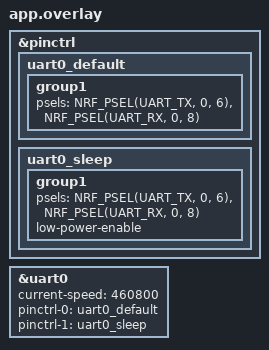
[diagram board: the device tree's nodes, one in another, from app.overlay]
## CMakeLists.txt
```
cmake_minimum_required(VERSION 3.20.0)

find_package(Zephyr REQUIRED HINTS $ENV{ZEPHYR_BASE})
project(gateway_nrf_central)

target_sources(app PRIVATE 
    src/main.c
    src/ble_central_mgr.c
    src/ble_node_slots.c
    src/uart_tx_bridge.c
    src/uart_tx_queue.c
)

target_include_directories(app PRIVATE
    src
    ../common
)
```

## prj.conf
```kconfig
# GPIO Driver
CONFIG_GPIO=y

# Console Output
CONFIG_PRINTK=y

# Zephyr Logging Subsystem
CONFIG_LOG=y
CONFIG_LOG_MODE_DEFERRED=y
CONFIG_LOG_BACKEND_SHOW_COLOR=y

# Output format for UF2 Bootloader
CONFIG_BUILD_OUTPUT_UF2=y

# USB CDC ACM Serial Console
CONFIG_SERIAL=y
CONFIG_CONSOLE=y
CONFIG_UART_CONSOLE=y
CONFIG_USB_DEVICE_STACK_NEXT=y
CONFIG_CDC_ACM_SERIAL_INITIALIZE_AT_BOOT=y
CONFIG_CDC_ACM_SERIAL_ENABLE_AT_BOOT=y

# High-Speed UART Bridge with EasyDMA (UARTE0 @ 460800 bps)
CONFIG_UART_ASYNC_API=y
CONFIG_UART_0_INTERRUPT_DRIVEN=n
CONFIG_UART_0_ASYNC=y


# Bluetooth Subsystem
CONFIG_BT=y
CONFIG_BT_CENTRAL=y
CONFIG_BT_SMP=y
CONFIG_BT_GATT_CLIENT=y

# Multi-Link Configuration (Up to 10 Concurrent Node Connections)
CONFIG_BT_MAX_CONN=10
CONFIG_BT_MAX_PAIRED=10
CONFIG_BT_CONN_TX_MAX=16
CONFIG_BT_BUF_ACL_TX_COUNT=16
CONFIG_BT_BUF_EVT_RX_COUNT=20

# High Throughput & MTU Settings
CONFIG_BT_L2CAP_TX_MTU=247
CONFIG_BT_BUF_ACL_RX_SIZE=251
CONFIG_BT_BUF_ACL_TX_SIZE=251
CONFIG_BT_CTLR_DATA_LENGTH_MAX=251
```

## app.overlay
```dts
&pinctrl {
    uart0_default: uart0_default {
        group1 {
			psels = <NRF_PSEL(UART_TX, 0, 6)>, <NRF_PSEL(UART_RX, 0, 8)>;
		};
    };

    uart0_sleep: uart0_sleep {
        group1 {
			psels = <NRF_PSEL(UART_TX, 0, 6)>, <NRF_PSEL(UART_RX, 0, 8)>;
            low-power-enable;
		};
    };
};

&uart0 {
    status = "okay";
    current-speed = <460800>;
    pinctrl-0 = <&uart0_default>;
    pinctrl-1 = <&uart0_sleep>;
    pinctrl-names = "default", "sleep";
};
```

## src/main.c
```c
#include <stdbool.h>
#include <stdint.h>
#include <string.h>

#include <zephyr/drivers/gpio.h>
#include <zephyr/kernel.h>
#include <zephyr/logging/log.h>
#include <zephyr/sys/printk.h>

#include "ble_central_mgr.h"
#include "ble_protocol_def.h"
#include "uart_frame_def.h"
#include "uart_tx_bridge.h"
#include "uart_tx_queue.h"

LOG_MODULE_REGISTER(gateway_main, LOG_LEVEL_INF);

static const struct gpio_dt_spec user_led = GPIO_DT_SPEC_GET(DT_ALIAS(led0), gpios);
#define LED_BLINK_INTERVAL_MS 1000

static void on_ble_connected(const ble_conn_context_t *ctx, const bt_addr_le_t *addr) {
    ARG_UNUSED(addr);
    uint8_t payload[sizeof(uart_v2_envelope_t) + sizeof(uart_node_status_pkt_t)];
    uart_v2_envelope_t *env = (uart_v2_envelope_t *)payload;
    uart_node_status_pkt_t *status = (uart_node_status_pkt_t *)(payload + sizeof(uart_v2_envelope_t));

    env->bridge_epoch = uart_tx_bridge_get_active_epoch();
    env->session_id = ctx->session_id;
    env->seq = ctx->seq;
    env->central_rx_mono_ms = ctx->rx_mono_ms;

    status->status = 1; /* 1 = Connected */
    memcpy(status->mac, ctx->mac, 6);

    uart_tx_queue_send(ctx->slot_id, UART_PKT_TYPE_NODE_STATUS_V2, payload, sizeof(payload));
}

static void on_ble_disconnected(const ble_conn_context_t *ctx, const bt_addr_le_t *addr, uint8_t reason) {
    ARG_UNUSED(addr);
    ARG_UNUSED(reason);
    uint8_t payload[sizeof(uart_v2_envelope_t) + sizeof(uart_node_status_pkt_t)];
    uart_v2_envelope_t *env = (uart_v2_envelope_t *)payload;
    uart_node_status_pkt_t *status = (uart_node_status_pkt_t *)(payload + sizeof(uart_v2_envelope_t));

    env->bridge_epoch = uart_tx_bridge_get_active_epoch();
    env->session_id = ctx->session_id;
    env->seq = ctx->seq;
    env->central_rx_mono_ms = ctx->rx_mono_ms;

    status->status = 0; /* 0 = Disconnected */
    memcpy(status->mac, ctx->mac, 6);

    uart_tx_queue_send(ctx->slot_id, UART_PKT_TYPE_NODE_STATUS_V2, payload, sizeof(payload));
}

static void on_vitals_received(const ble_conn_context_t *ctx, const vitals_packet_t *vitals) {
    uint8_t payload[sizeof(uart_v2_envelope_t) + sizeof(vitals_packet_t)];
    uart_v2_envelope_t *env = (uart_v2_envelope_t *)payload;

    env->bridge_epoch = uart_tx_bridge_get_active_epoch();
    env->session_id = ctx->session_id;
    env->seq = ctx->seq;
    env->central_rx_mono_ms = ctx->rx_mono_ms;

    memcpy(payload + sizeof(uart_v2_envelope_t), vitals, sizeof(vitals_packet_t));
    uart_tx_queue_send(ctx->slot_id, UART_PKT_TYPE_VITALS_V2, payload, sizeof(payload));
}

static void on_ecg_received(const ble_conn_context_t *ctx, const int16_t *samples, uint16_t count) {
    uint8_t sample_bytes = (uint8_t)(count * sizeof(int16_t));
    if (sample_bytes > 100) {
        sample_bytes = 100;
    }

    uint8_t payload[sizeof(uart_v2_envelope_t) + 100];
    uart_v2_envelope_t *env = (uart_v2_envelope_t *)payload;

    env->bridge_epoch = uart_tx_bridge_get_active_epoch();
    env->session_id = ctx->session_id;
    env->seq = ctx->seq;
    env->central_rx_mono_ms = ctx->rx_mono_ms;

    memcpy(payload + sizeof(uart_v2_envelope_t), samples, sample_bytes);
    uart_tx_queue_send(ctx->slot_id, UART_PKT_TYPE_ECG_V2, payload, (uint8_t)(sizeof(uart_v2_envelope_t) + sample_bytes));
}

static void on_raw_received(const ble_conn_context_t *ctx, const uint8_t *data, uint16_t len) {
    ARG_UNUSED(ctx);
    ARG_UNUSED(data);
    ARG_UNUSED(len);
}

static const ble_central_callbacks_t ble_callbacks = {
    .connected = on_ble_connected,
    .disconnected = on_ble_disconnected,
    .vitals_received = on_vitals_received,
    .ecg_received = on_ecg_received,
    .raw_received = on_raw_received,
};

/* ══════════════════════════════════════════════════════════════
 *  Main Application Entry Point
 * ════════════════════════════════════════════════════════════ */
int main(void) {
    int ret;
    bool led_state = false;
    uint32_t heartbeat_cnt = 0;

    if (gpio_is_ready_dt(&user_led)) {
        gpio_pin_configure_dt(&user_led, GPIO_OUTPUT_ACTIVE);
    }

    printk("\n==================================================\n");
    printk("  [Wearable Gateway] Zephyr BLE Central & Bridge    \n");
    printk("  Board: Pro Micro nRF52840 (UF2)                  \n");
    printk("  Inter-Chip UART Bridge @ 460800 bps              \n");
    printk("==================================================\n\n");

    ret = uart_tx_bridge_init();
    if (ret != 0) {
        LOG_ERR("UART Bridge init failed (%d)", ret);
    }

    uart_tx_queue_init();

    ret = ble_central_mgr_init(&ble_callbacks);
    if (ret != 0) {
        LOG_ERR("BLE Central Manager init failed (err %d)", ret);
    } else {
        LOG_INF("BLE Central Manager initialized. Waiting for '%s'...", BLE_DEV_NAME_PREFIX);
    }

    while (1) {
        gpio_pin_toggle_dt(&user_led);
        led_state = !led_state;

        uart_tx_bridge_poll_handshake();

        uart_tx_queue_stats_t q_stats;
        uint32_t q_pending = uart_tx_queue_get_stats(&q_stats);

        LOG_INF("[HEARTBEAT #%03u] Nodes: %u/10 (Sub: %u) | Q: %u/32 (Sent: %u, Drop: %u) | Uptime: %lld ms",
                heartbeat_cnt++,
                ble_central_mgr_get_connected_count(),
                ble_central_mgr_get_subscribed_count(),
                q_pending,
                q_stats.sent_count,
                q_stats.dropped_count,
                k_uptime_get());

        k_msleep(LED_BLINK_INTERVAL_MS);
    }


    return 0;
}
```

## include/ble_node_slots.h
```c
#ifndef BLE_NODE_SLOTS_H
#define BLE_NODE_SLOTS_H

/* Standard C Libraries */
#include <stdbool.h>
#include <stdint.h>

/* Zephyr System Headers */
#include <zephyr/types.h>
#include <zephyr/bluetooth/bluetooth.h> 
#include <zephyr/bluetooth/conn.h>     
#include <zephyr/bluetooth/gatt.h>      

#ifndef BLE_NODE_MAX_SLOTS
#if defined(CONFIG_BT_MAX_CONN)
#define BLE_NODE_MAX_SLOTS CONFIG_BT_MAX_CONN
#else
#define BLE_NODE_MAX_SLOTS 10U
#endif
#endif


typedef enum {
    NODE_STATE_FREE = 0,
    NODE_STATE_CONNECTING,
    NODE_STATE_CONNECTED,
    NODE_STATE_DISCOVERING,
    NODE_STATE_SUBSCRIBED
} ble_node_state_t ;

typedef struct {
    uint8_t slot_id;                   /* 0 .. 9 */
    bool is_used;
    ble_node_state_t state;
    bt_addr_le_t addr;                 /* MAC của Node */
    struct bt_conn *conn;              /* Con trỏ kết nối Zephyr */
    uint16_t tx_char_val_handle;      
    uint16_t cccd_handle;             
    struct bt_gatt_exchange_params mtu_params;
    struct bt_gatt_discover_params discover_params;
    struct bt_gatt_subscribe_params subscribe_params;
} ble_node_slot_t;

void ble_node_slots_init(void);

  
ble_node_slot_t *ble_node_slot_alloc(const bt_addr_le_t *addr); 

  
void ble_node_slot_free(ble_node_slot_t *slot); 

  
ble_node_slot_t *ble_node_slot_find_by_addr(const bt_addr_le_t *addr);

  
ble_node_slot_t *ble_node_slot_find_by_conn(const struct bt_conn *conn);

  
uint8_t ble_node_slots_get_active_count(void);

  
uint8_t ble_node_slots_get_subscribed_count(void);

#endif
```

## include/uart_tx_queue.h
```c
#ifndef UART_TX_QUEUE_H
#define UART_TX_QUEUE_H

#include <stddef.h>
#include <stdint.h>
#include <stdbool.h>

#include "uart_frame_def.h"

#ifdef __cplusplus
extern "C" {
#endif

#define UART_TX_QUEUE_DEPTH 32

/* Fixed-size flat item struct, aligned to 4 bytes */
typedef struct {
    uint8_t node_id;
    uint8_t pkt_type;
    uint8_t len;
    uint8_t payload[UART_MAX_PAYLOAD_LEN]; /* 128 bytes */
} uart_tx_item_t;

typedef struct {
    uint32_t queued_count;
    uint32_t sent_count;
    uint32_t dropped_count;
    uint32_t error_count;
} uart_tx_queue_stats_t;

/**
 * @brief Initialize the UART TX Queue module and clear stats.
 */
void uart_tx_queue_init(void);

/**
 * @brief Non-blocking producer call to enqueue a frame for transmission.
 *
 * @param node_id Target/Source node index (0..9)
 * @param pkt_type Packet type (UART_PKT_TYPE_*)
 * @param payload Pointer to payload buffer
 * @param len Payload length (1..128)
 * @return 0 on success, -ENOMEM if queue is full, -EINVAL if params invalid
 */
int uart_tx_queue_send(uint8_t node_id, uint8_t pkt_type, const void *payload, uint8_t len);

/**
 * @brief Retrieve an item from the queue (used by consumer worker).
 *
 * @param item Pointer to output item struct
 * @param timeout_ms Timeout in milliseconds (0 = no wait, -1 = forever)
 * @return 0 on success, negative error code otherwise
 */
int uart_tx_queue_get(uart_tx_item_t *item, int32_t timeout_ms);

/**
 * @brief Get queue statistics and current count of pending items.
 *
 * @param stats Output pointer to copy stats into (optional, can be NULL)
 * @return Current number of items waiting in queue
 */
uint32_t uart_tx_queue_get_stats(uart_tx_queue_stats_t *stats);

#ifdef __cplusplus
}
#endif

#endif /* UART_TX_QUEUE_H */
```

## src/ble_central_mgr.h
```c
/*
 * Copyright (c) 2026 Wearable Gateway Project
 *
 * ble_central_mgr.h - BLE Central Manager for Wearable Gateway
 * Handles Active Scanning, Target Node Matching, Connection Lifecycle,
 * ATT MTU Negotiation, GATT Discovery, and Characteristic Subscription.
 */

#ifndef BLE_CENTRAL_MGR_H
#define BLE_CENTRAL_MGR_H

/* Standard C Libraries */
#include <stdbool.h>
#include <stdint.h>

/* Zephyr System Headers */
#include <zephyr/types.h>
#include <zephyr/bluetooth/bluetooth.h>
#include <zephyr/bluetooth/conn.h>

/* Project Local Headers */
#include "ble_node_slots.h"
#include "ble_protocol_def.h"

/**
 * @brief Application event callbacks registered with BLE Central Manager.
 */
typedef struct {
    void (*connected)(const ble_conn_context_t *ctx, const bt_addr_le_t *addr);
    void (*disconnected)(const ble_conn_context_t *ctx, const bt_addr_le_t *addr, uint8_t reason);
    void (*vitals_received)(const ble_conn_context_t *ctx, const vitals_packet_t *vitals);
    void (*ecg_received)(const ble_conn_context_t *ctx, const int16_t *samples, uint16_t count);
    void (*raw_received)(const ble_conn_context_t *ctx, const uint8_t *data, uint16_t len);
} ble_central_callbacks_t;

/**
 * @brief Initialize the Bluetooth stack and start BLE Central manager.
 *
 * @param cbs Pointer to callback structure (must have static/persistent lifetime).
 * @return 0 on success, or negative error code on failure.
 */
int ble_central_mgr_init(const ble_central_callbacks_t *cbs);

/**
 * @brief Check if a peripheral node is currently connected.
 *
 * @return true if connected, false otherwise.
 */
bool ble_central_mgr_is_connected(void);

/**
 * @brief Start active BLE scanning for target nodes.
 *
 * @return 0 on success, or negative error code on failure.
 */
int ble_central_mgr_scan_start(void);

/**
 * @brief Stop active BLE scanning.
 *
 * @return 0 on success, or negative error code on failure.
 */
int ble_central_mgr_scan_stop(void);

uint8_t ble_central_mgr_get_connected_count(void);

uint8_t ble_central_mgr_get_subscribed_count(void);

/**
 * @brief Send a downlink command payload to a node via BLE GATT Write Request (0x1402).
 *
 * @param slot_id Slot index (0 .. BLE_NODE_MAX_SLOTS - 1)
 * @param data    Command payload bytes (e.g. CMD_MODE_CFG, CMD_THR, etc.)
 * @param len     Length of command payload in bytes
 * @return 0 on success, -EINVAL on invalid args, -ENOTCONN if not connected/discovered,
 *         -EBUSY if a write is already in progress for this slot.
 */
int ble_central_mgr_write_cmd(uint8_t slot_id, const uint8_t *data, uint16_t len);

#endif /* BLE_CENTRAL_MGR_H */
```

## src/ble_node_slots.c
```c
/* Standard C Libraries */
#include <stdbool.h>
#include <stdint.h>
#include <string.h>

#ifndef HOST_TEST
/* Zephyr System Headers */
#include <zephyr/kernel.h>
#include <zephyr/logging/log.h>
LOG_MODULE_REGISTER(ble_node_slots, LOG_LEVEL_INF);
#endif

/* Project Local Headers */
#include "ble_node_slots.h"

static ble_node_slot_t s_slots[BLE_NODE_MAX_SLOTS];
static uint32_t s_global_session_counter = 1;

static void convert_addr_to_mac_be(uint8_t *mac_be, const bt_addr_le_t *addr) {
    if (!mac_be) return;
    if (addr) {
        /* Convert Zephyr Little-Endian (addr->a.val[0]=LSB) to Canonical Big-Endian (mac_be[0]=MSB) */
        mac_be[0] = addr->a.val[5];
        mac_be[1] = addr->a.val[4];
        mac_be[2] = addr->a.val[3];
        mac_be[3] = addr->a.val[2];
        mac_be[4] = addr->a.val[1];
        mac_be[5] = addr->a.val[0];
    } else {
        memset(mac_be, 0, 6);
    }
}

static uint32_t allocate_next_session_id(void) {
    uint32_t session = s_global_session_counter++;
    if (session == 0) {
        session = s_global_session_counter++;
    }
    return session;
}

void ble_node_slots_init(void) {
    memset(s_slots, 0, sizeof(s_slots));
    for (uint32_t i = 0; i < BLE_NODE_MAX_SLOTS; i++) {
        s_slots[i].slot_id = (uint8_t)i;
        s_slots[i].is_used = false;
        s_slots[i].state = NODE_STATE_FREE;
        s_slots[i].conn = NULL;
        s_slots[i].session_id = 0;
        s_slots[i].seq = 0;
    }
    s_global_session_counter = 1;
}

ble_node_slot_t *ble_node_slot_alloc(const bt_addr_le_t *addr) {
    /* 1. Ưu tiên tái cấp phát cho MAC cũ đã từng gắn với slot này */
    if (addr) {
        for (uint32_t i = 0; i < BLE_NODE_MAX_SLOTS; i++) {
            if (!s_slots[i].is_used && bt_addr_le_cmp(&s_slots[i].addr, addr) == 0) {
                s_slots[i].slot_id = (uint8_t)i;
                s_slots[i].is_used = true;
                s_slots[i].state = NODE_STATE_CONNECTING;
                s_slots[i].session_id = allocate_next_session_id();
                s_slots[i].seq = 0;
                s_slots[i].rx_char_val_handle = 0;
                s_slots[i].write_in_progress = false;
                convert_addr_to_mac_be(s_slots[i].mac_be, addr);
                return &s_slots[i];
            }
        }
    }

    /* 2. Cấp phát slot rảnh mới */
    for (uint32_t i = 0; i < BLE_NODE_MAX_SLOTS; i++) {
        if (!s_slots[i].is_used) {
            memset(&s_slots[i], 0, sizeof(ble_node_slot_t));
            s_slots[i].slot_id = (uint8_t)i;
            s_slots[i].is_used = true;
            s_slots[i].state = NODE_STATE_CONNECTING;
            s_slots[i].session_id = allocate_next_session_id();
            s_slots[i].seq = 0;

            if (addr) {
                bt_addr_le_copy(&s_slots[i].addr, addr);
                convert_addr_to_mac_be(s_slots[i].mac_be, addr);
            }
            return &s_slots[i];
        }
    }
    return NULL;
}

void ble_node_slot_free(ble_node_slot_t *slot) {
    if (!slot) {
        return;
    }

    if (slot->conn) {
        bt_conn_unref(slot->conn);
        slot->conn = NULL;
    }

    /* Giữ nguyên slot->addr để phục vụ cơ chế Static MAC Reconnect */
    slot->is_used = false;
    slot->state = NODE_STATE_FREE;
    slot->session_id = 0;
    slot->seq = 0;
    slot->rx_char_val_handle = 0;
    slot->write_in_progress = false;
}

ble_node_slot_t *ble_node_slot_find_by_addr(const bt_addr_le_t *addr) {
    if (!addr) {
        return NULL;
    }

    for (uint32_t i = 0; i < BLE_NODE_MAX_SLOTS; i++) {
        if (s_slots[i].is_used && bt_addr_le_cmp(addr, &s_slots[i].addr) == 0) {
            return &s_slots[i];
        }
    }
    return NULL;
}

ble_node_slot_t *ble_node_slot_find_by_conn(const struct bt_conn *conn) {
    if (!conn) {
        return NULL;
    }

    for (uint32_t i = 0; i < BLE_NODE_MAX_SLOTS; i++) {
        if (s_slots[i].is_used && s_slots[i].conn == conn) {
            return &s_slots[i];
        }
    }
    return NULL;
}

ble_node_slot_t *ble_node_slot_find_by_session(uint32_t session_id) {
    if (session_id == 0) {
        return NULL;
    }

    for (uint32_t i = 0; i < BLE_NODE_MAX_SLOTS; i++) {
        if (s_slots[i].is_used && s_slots[i].session_id == session_id) {
            return &s_slots[i];
        }
    }
    return NULL;
}

ble_node_slot_t *ble_node_slot_get(uint8_t slot_id) {
    if (slot_id >= BLE_NODE_MAX_SLOTS) {
        return NULL;
    }
    return &s_slots[slot_id];
}

uint32_t ble_node_slot_next_seq(ble_node_slot_t *slot) {
    if (!slot) return 0;
    slot->seq++;
    return slot->seq;
}

bool ble_node_slot_capture_context(ble_node_slot_t *slot, ble_conn_context_t *ctx_out, uint64_t mono_ms) {
    if (!slot || !ctx_out || !slot->is_used || slot->session_id == 0) {
        return false;
    }

    ctx_out->slot_id = slot->slot_id;
    ctx_out->session_id = slot->session_id;
    ctx_out->seq = ble_node_slot_next_seq(slot);
    memcpy(ctx_out->mac, slot->mac_be, 6);
    ctx_out->rx_mono_ms = mono_ms;
    return true;
}

uint8_t ble_node_slots_get_active_count(void) {
    uint8_t count = 0;
    for (uint32_t i = 0; i < BLE_NODE_MAX_SLOTS; i++) {
        if (s_slots[i].is_used) {
            count++;
        }
    }
    return count;
}

uint8_t ble_node_slots_get_subscribed_count(void) {
    uint8_t count = 0;
    for (uint32_t i = 0; i < BLE_NODE_MAX_SLOTS; i++) {
        if (s_slots[i].is_used && s_slots[i].state == NODE_STATE_SUBSCRIBED) {
            count++;
        }
    }
    return count;
}
```

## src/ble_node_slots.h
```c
#ifndef BLE_NODE_SLOTS_H
#define BLE_NODE_SLOTS_H

/* Standard C Libraries */
#include <stdbool.h>
#include <stdint.h>
#include <stddef.h>

/* Zephyr System Headers */
#include <zephyr/types.h>
#include <zephyr/bluetooth/bluetooth.h> 
#include <zephyr/bluetooth/conn.h>     
#include <zephyr/bluetooth/gatt.h>      

#include "uart_frame_def.h"

#ifndef BLE_NODE_MAX_SLOTS
#if defined(CONFIG_BT_MAX_CONN)
#define BLE_NODE_MAX_SLOTS CONFIG_BT_MAX_CONN
#else
#define BLE_NODE_MAX_SLOTS 10U
#endif
#endif

typedef enum {
    NODE_STATE_FREE = 0,
    NODE_STATE_CONNECTING,
    NODE_STATE_CONNECTED,
    NODE_STATE_DISCOVERING,
    NODE_STATE_SUBSCRIBED
} ble_node_state_t;

typedef struct {
    uint8_t slot_id;                   /* 0 .. 9 */
    bool is_used;
    ble_node_state_t state;
    bt_addr_le_t addr;                 /* Native BLE Address (Little-Endian in addr.a.val) */
    uint8_t mac_be[6];                 /* Big-Endian display format matching GC9A01 LCD */
    uint32_t session_id;               /* Unique session id for this connection */
    uint32_t seq;                      /* Monotonically increasing sequence number */
    struct bt_conn *conn;              /* Zephyr connection pointer */
    uint16_t tx_char_val_handle;      
    uint16_t cccd_handle;             
    uint16_t rx_char_val_handle;       /* RX Char 0x1402 value handle for downlink write */
    bool write_in_progress;            /* In-flight bt_gatt_write lock */
    struct bt_gatt_write_params write_params; /* Persistent Zephyr write parameters struct */
    uint8_t write_buf[UART_MAX_PAYLOAD_LEN];  /* Static payload buffer for write */
    struct bt_gatt_exchange_params mtu_params;
    struct bt_gatt_discover_params discover_params;
    struct bt_gatt_subscribe_params subscribe_params;
} ble_node_slot_t;

/* Context captured in callbacks */
typedef struct {
    uint8_t  slot_id;                  /* 0 .. 9 */
    uint32_t session_id;               /* Non-zero session id */
    uint32_t seq;                      /* Sequence number for this sample */
    uint8_t  mac[6];                   /* Canonical Big-Endian MAC */
    uint64_t rx_mono_ms;               /* Monotonic timestamp */
} ble_conn_context_t;

void ble_node_slots_init(void);

ble_node_slot_t *ble_node_slot_alloc(const bt_addr_le_t *addr);

void ble_node_slot_free(ble_node_slot_t *slot);

ble_node_slot_t *ble_node_slot_find_by_addr(const bt_addr_le_t *addr);

ble_node_slot_t *ble_node_slot_find_by_conn(const struct bt_conn *conn);

ble_node_slot_t *ble_node_slot_find_by_session(uint32_t session_id);

ble_node_slot_t *ble_node_slot_get(uint8_t slot_id);

uint32_t ble_node_slot_next_seq(ble_node_slot_t *slot);

bool ble_node_slot_capture_context(ble_node_slot_t *slot, ble_conn_context_t *ctx_out, uint64_t mono_ms);

uint8_t ble_node_slots_get_active_count(void);

uint8_t ble_node_slots_get_subscribed_count(void);

#endif /* BLE_NODE_SLOTS_H */
```

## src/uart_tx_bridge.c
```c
/* Standard C Libraries */
#include <stddef.h>
#include <stdint.h>
#include <string.h>

#ifndef HOST_TEST
/* Zephyr System Headers */
#include <zephyr/device.h>
#include <zephyr/drivers/uart.h>
#include <zephyr/kernel.h>
#include <zephyr/logging/log.h>
#endif

/* Project Local Headers */
#include "uart_frame_def.h"
#include "uart_tx_bridge.h"
#include "ble_central_mgr.h"

#if (defined(HOST_TEST) || defined(HOST_UNIT_TEST)) && defined(__GNUC__)
__attribute__((weak)) int ble_central_mgr_write_cmd(uint8_t slot_id, const uint8_t *data, uint16_t len) {
    (void)slot_id;
    (void)data;
    (void)len;
    return 0;
}
#endif

#ifndef HOST_TEST
LOG_MODULE_REGISTER(uart_tx_bridge, LOG_LEVEL_INF);
#endif

/* ══════════════════════════════════════════════════════════════
 *  Central Bridge FSM Implementation
 * ════════════════════════════════════════════════════════════ */

void central_bridge_fsm_init(central_bridge_fsm_t *fsm, uint32_t boot_nonce) {
    if (!fsm) return;
    memset(fsm, 0, sizeof(*fsm));
    fsm->state = CENTRAL_LINK_UNSYNCED;
    fsm->boot_nonce = boot_nonce;
}

int central_bridge_create_hello(central_bridge_fsm_t *fsm, uart_ctrl_hello_pkt_t *hello_out) {
    if (!fsm || !hello_out) return -1;
    hello_out->version = UART_BRIDGE_PROTOCOL_VERSION;
    hello_out->boot_nonce = fsm->boot_nonce;
    hello_out->reserved = 0;
    fsm->hello_sent_count++;
    return 0;
}

int central_bridge_handle_sync(central_bridge_fsm_t *fsm, const uart_ctrl_sync_pkt_t *sync) {
    if (!fsm || !sync) return -1;

    if (sync->version != UART_BRIDGE_PROTOCOL_VERSION) {
        return -2; /* Protocol version mismatch */
    }

    if (sync->boot_nonce != fsm->boot_nonce) {
        fsm->stale_sync_drops++;
        return -3; /* Stale sync from an earlier boot nonce */
    }

    if (sync->status != 1) {
        return -4; /* Sync rejected by peer */
    }

    fsm->active_epoch = sync->bridge_epoch;
    fsm->state = CENTRAL_LINK_SYNCED;
    fsm->sync_recv_count++;
    return 0;
}

int central_bridge_handle_snapshot_req(central_bridge_fsm_t *fsm, const uart_snapshot_req_pkt_t *req) {
    if (!fsm || !req) return -1;
    if (fsm->state != CENTRAL_LINK_SYNCED) {
        return -2;
    }
    if (req->bridge_epoch != fsm->active_epoch) {
        return -3; /* Epoch mismatch */
    }

    fsm->snapshot_tx_id = req->transaction_id;
    return 0;
}

int central_bridge_create_snapshot_end(central_bridge_fsm_t *fsm, uart_snapshot_end_pkt_t *end_out) {
    if (!fsm || !end_out) return -1;
    if (fsm->state != CENTRAL_LINK_SYNCED) {
        return -2;
    }

    end_out->bridge_epoch = fsm->active_epoch;
    end_out->transaction_id = fsm->snapshot_tx_id;
    end_out->slot_count = MAX_NODES_SUPPORTED;
    end_out->reserved = 0;
    return 0;
}

void central_bridge_barrier_reset(central_bridge_fsm_t *fsm) {
    if (!fsm) return;
    fsm->state = CENTRAL_LINK_UNSYNCED;
    fsm->active_epoch = 0;
    fsm->snapshot_tx_id = 0;
}

int central_bridge_dispatch_downlink(uint8_t node_id, const uint8_t *payload, uint8_t len) {
    if (node_id >= MAX_NODES_SUPPORTED || !payload || len == 0) {
        return -1;
    }
    return ble_central_mgr_write_cmd(node_id, payload, len);
}

/* ══════════════════════════════════════════════════════════════
 *  Zephyr EasyDMA Hardware Bridge Driver (Target Only)
 * ════════════════════════════════════════════════════════════ */
#ifndef HOST_TEST

#include <zephyr/random/random.h>
#include "ble_node_slots.h"
#include "uart_tx_queue.h"

#define UART_TX_BUF_SIZE 1024
#define UART_RX_BUF_SIZE 256

/*
 * EasyDMA buffers: Must reside in Data RAM (0x20000000 - 0x2003FFFF)
 * on Nordic nRF52840. Static allocation guarantees RAM residency.
 */
static uint8_t dma_tx_buf[UART_TX_BUF_SIZE];
static uint8_t s_rx_buf_0[UART_RX_BUF_SIZE];
static uint8_t s_rx_buf_1[UART_RX_BUF_SIZE];
static uint8_t *s_next_rx_buf = s_rx_buf_1;

/* Synchronization semaphore: Signaled when EasyDMA ENDTX event fires */
static struct k_sem tx_done_sem;

static struct k_mutex tx_mutex;
static central_bridge_fsm_t s_bridge_fsm;

static const struct device *const s_uart_dev = DEVICE_DT_GET(DT_NODELABEL(uart0));

uint64_t uart_tx_bridge_get_active_epoch(void) {
    return s_bridge_fsm.active_epoch;
}

typedef enum {
    CENTRAL_RX_WAIT_SOF = 0,
    CENTRAL_RX_READ_NODE,
    CENTRAL_RX_READ_TYPE,
    CENTRAL_RX_READ_LEN,
    CENTRAL_RX_READ_PAYLOAD,
    CENTRAL_RX_CHECK_CRC,
} central_rx_state_t;

static central_rx_state_t s_rx_state = CENTRAL_RX_WAIT_SOF;
static uint8_t s_rx_node_id;
static uint8_t s_rx_pkt_type;
static uint8_t s_rx_len;
static uint8_t s_rx_idx;
static uint8_t s_rx_payload[UART_MAX_PAYLOAD_LEN];
static uint8_t s_rx_crc_buf[3 + UART_MAX_PAYLOAD_LEN];

static void central_dispatch_frame(uint8_t node_id, uint8_t pkt_type, const uint8_t *payload, uint8_t len) {
    (void)node_id;
    if (pkt_type == UART_PKT_TYPE_CONTROL_SYNC_REQ) {
        LOG_INF("🔄 Received SYNC_REQ from ESP32 -> re-broadcasting HELLO");
        uart_ctrl_hello_pkt_t hello;
        central_bridge_create_hello(&s_bridge_fsm, &hello);
        uart_tx_queue_send(0, UART_PKT_TYPE_CONTROL_HELLO, &hello, sizeof(hello));
        return;
    }

    if (pkt_type == UART_PKT_TYPE_CONTROL_SYNC) {
        if (len >= sizeof(uart_ctrl_sync_pkt_t)) {
            const uart_ctrl_sync_pkt_t *sync = (const uart_ctrl_sync_pkt_t *)payload;
            int ret = central_bridge_handle_sync(&s_bridge_fsm, sync);
            if (ret == 0) {
                LOG_INF("🤝 Central bridge SYNC established: epoch=%llu", (unsigned long long)sync->bridge_epoch);
            } else {
                LOG_WRN("⚠️ Central bridge SYNC rejected (err %d)", ret);
            }
        }
        return;
    }

    if (pkt_type == UART_PKT_TYPE_SNAPSHOT_REQ) {
        if (len >= sizeof(uart_snapshot_req_pkt_t)) {
            const uart_snapshot_req_pkt_t *req = (const uart_snapshot_req_pkt_t *)payload;
            if (central_bridge_handle_snapshot_req(&s_bridge_fsm, req) == 0) {
                LOG_INF("📋 Responding to snapshot request: tx_id=%u", (unsigned)req->transaction_id);
                for (uint8_t slot_idx = 0; slot_idx < MAX_NODES_SUPPORTED; slot_idx++) {
                    ble_node_slot_t *slot = ble_node_slot_get(slot_idx);
                    uint8_t status_buf[sizeof(uart_v2_envelope_t) + sizeof(uart_node_status_pkt_t)];
                    uart_v2_envelope_t *env = (uart_v2_envelope_t *)status_buf;
                    uart_node_status_pkt_t *st = (uart_node_status_pkt_t *)(status_buf + sizeof(uart_v2_envelope_t));

                    env->bridge_epoch = s_bridge_fsm.active_epoch;
                    env->session_id = (slot && slot->is_used) ? slot->session_id : 0;
                    env->seq = (slot && slot->is_used) ? slot->seq : 0;
                    env->central_rx_mono_ms = (uint64_t)k_uptime_get();

                    st->status = (slot && slot->is_used && slot->state >= NODE_STATE_CONNECTED) ? 1 : 0;
                    if (slot && slot->is_used) {
                        memcpy(st->mac, slot->mac_be, 6);
                    } else {
                        memset(st->mac, 0, 6);
                    }

                    uart_tx_queue_send(slot_idx, UART_PKT_TYPE_NODE_STATUS_V2, status_buf, sizeof(status_buf));
                }

                uart_snapshot_end_pkt_t end;
                if (central_bridge_create_snapshot_end(&s_bridge_fsm, &end) == 0) {
                    uart_tx_queue_send(0, UART_PKT_TYPE_SNAPSHOT_END, &end, sizeof(end));
                }
            }
        }
        return;
    }

    if (pkt_type == UART_PKT_TYPE_DOWNLINK) {
        LOG_INF("📥 Received DOWNLINK frame for slot %u (len %u)", (unsigned)node_id, (unsigned)len);
        int ret = ble_central_mgr_write_cmd(node_id, payload, len);
        if (ret != 0) {
            LOG_WRN("⚠️ Failed to dispatch downlink to slot %u (err %d)", (unsigned)node_id, ret);
        }
        return;
    }
}

static void central_parse_byte(uint8_t b) {
    switch (s_rx_state) {
    case CENTRAL_RX_WAIT_SOF:
        if (b == UART_FRAME_SOF) {
            s_rx_state = CENTRAL_RX_READ_NODE;
        }
        break;
    case CENTRAL_RX_READ_NODE:
        if (b < MAX_NODES_SUPPORTED) {
            s_rx_node_id = b;
            s_rx_crc_buf[0] = b;
            s_rx_state = CENTRAL_RX_READ_TYPE;
        } else {
            s_rx_state = (b == UART_FRAME_SOF) ? CENTRAL_RX_READ_NODE : CENTRAL_RX_WAIT_SOF;
        }
        break;
    case CENTRAL_RX_READ_TYPE:
        s_rx_pkt_type = b;
        s_rx_crc_buf[1] = b;
        s_rx_state = CENTRAL_RX_READ_LEN;
        break;
    case CENTRAL_RX_READ_LEN:
        if (b > 0 && b <= UART_MAX_PAYLOAD_LEN) {
            s_rx_len = b;
            s_rx_crc_buf[2] = b;
            s_rx_idx = 0;
            s_rx_state = CENTRAL_RX_READ_PAYLOAD;
        } else {
            s_rx_state = (b == UART_FRAME_SOF) ? CENTRAL_RX_READ_NODE : CENTRAL_RX_WAIT_SOF;
        }
        break;
    case CENTRAL_RX_READ_PAYLOAD:
        s_rx_payload[s_rx_idx] = b;
        s_rx_crc_buf[3 + s_rx_idx] = b;
        s_rx_idx++;
        if (s_rx_idx == s_rx_len) {
            s_rx_state = CENTRAL_RX_CHECK_CRC;
        }
        break;
    case CENTRAL_RX_CHECK_CRC: {
        uint8_t expected_crc = uart_crc8_calc(s_rx_crc_buf, 3 + s_rx_len);
        if (b == expected_crc) {
            central_dispatch_frame(s_rx_node_id, s_rx_pkt_type, s_rx_payload, s_rx_len);
        } else {
            LOG_WRN("UART RX CRC mismatch (calc 0x%02X != recv 0x%02X)", expected_crc, b);
        }
        s_rx_state = CENTRAL_RX_WAIT_SOF;
        break;
    }
    default:
        s_rx_state = CENTRAL_RX_WAIT_SOF;
        break;
    }
}

static void uart_async_callback(const struct device *dev, struct uart_event *evt, void *user_data) {
    ARG_UNUSED(user_data);

    switch (evt->type) {
    case UART_TX_DONE:
        LOG_DBG("UART EasyDMA TX Complete (%zu bytes)", evt->data.tx.len);
        k_sem_give(&tx_done_sem);
        break;

    case UART_TX_ABORTED:
        LOG_WRN("UART EasyDMA TX Aborted");
        k_sem_give(&tx_done_sem);
        break;

    case UART_RX_RDY:
        if (evt->data.rx.len > 0) {
            const uint8_t *buf = evt->data.rx.buf + evt->data.rx.offset;
            for (size_t i = 0; i < evt->data.rx.len; i++) {
                central_parse_byte(buf[i]);
            }
        }
        break;

    case UART_RX_BUF_REQUEST:
        /* Provide next buffer for continuous seamless DMA reception */
        uart_rx_buf_rsp(dev, s_next_rx_buf, UART_RX_BUF_SIZE);
        break;

    case UART_RX_BUF_RELEASED:
        s_next_rx_buf = evt->data.rx_buf.buf;
        break;

    case UART_RX_DISABLED:
        /* Re-enable double-buffered reception without flood logging (20ms = 20,000 us) */
        uart_rx_enable(dev, s_rx_buf_0, UART_RX_BUF_SIZE, 20000);
        break;

    default:
        break;
    }
}

int uart_tx_bridge_init(void) {
    if (!device_is_ready(s_uart_dev)) {
        LOG_ERR("UART0 device is NOT ready!");
        return -ENODEV;
    }

    k_mutex_init(&tx_mutex);
    k_sem_init(&tx_done_sem, 0, 1);
    int ret = uart_callback_set(s_uart_dev, uart_async_callback, NULL);
    if (ret != 0) {
        LOG_ERR("Failed to set UART async callback: %d", ret);
        return ret;
    }

    /* Enable continuous double-buffered EasyDMA RX (20 ms = 20,000 us timeout) */
    ret = uart_rx_enable(s_uart_dev, s_rx_buf_0, sizeof(s_rx_buf_0), 20000);
    if (ret != 0) {
        LOG_WRN("UART async RX enable returned %d (will retry)", ret);
    }

    central_bridge_fsm_init(&s_bridge_fsm, sys_rand32_get());

    uart_ctrl_hello_pkt_t hello;
    central_bridge_create_hello(&s_bridge_fsm, &hello);
    uart_tx_bridge_send_frame(0, UART_PKT_TYPE_CONTROL_HELLO, &hello, sizeof(hello));

    LOG_INF("UART0 EasyDMA Bridge initialized at 460800 bps (TX: P0.06 | RX: P0.08) - Sent HELLO (nonce=0x%08X)", (unsigned)s_bridge_fsm.boot_nonce);
    return 0;
}

void uart_tx_bridge_poll_handshake(void) {
    if (s_bridge_fsm.state != CENTRAL_LINK_SYNCED) {
        static int64_t last_hello_mono = 0;
        int64_t now = k_uptime_get();
        if (now - last_hello_mono >= 2000) {
            last_hello_mono = now;
            uart_ctrl_hello_pkt_t hello;
            central_bridge_create_hello(&s_bridge_fsm, &hello);
            uart_tx_bridge_send_frame(0, UART_PKT_TYPE_CONTROL_HELLO, &hello, sizeof(hello));
            LOG_INF("🔄 Retrying bridge handshake: Sent HELLO (nonce=0x%08X)...", (unsigned)s_bridge_fsm.boot_nonce);
        }
    }
}

int uart_tx_bridge_send(const uint8_t *data, size_t len) {
    if (!device_is_ready(s_uart_dev) || data == NULL || len == 0 || len > UART_TX_BUF_SIZE) {
        return -EINVAL;
    }

    k_mutex_lock(&tx_mutex, K_FOREVER);

    memcpy(dma_tx_buf, data, len);

    int ret = uart_tx(s_uart_dev, dma_tx_buf, len, SYS_FOREVER_US);
    if (ret < 0) {
        LOG_ERR("uart_tx failed: %d", ret);
        k_mutex_unlock(&tx_mutex);
        return ret;
    }

    ret = k_sem_take(&tx_done_sem, K_MSEC(50));
    if (ret != 0) {
        LOG_ERR("UART EasyDMA TX timeout, aborting transmission");
        uart_tx_abort(s_uart_dev);
    }

    k_mutex_unlock(&tx_mutex);
    return ret;
}

int uart_tx_bridge_send_frame(uint8_t node_id, uint8_t pkt_type, const void *payload, uint8_t len) {
    k_mutex_lock(&tx_mutex, K_FOREVER);

    int frame_len = uart_frame_pack(dma_tx_buf, sizeof(dma_tx_buf), node_id, pkt_type, payload, len);
    if (frame_len < 0) {
        LOG_ERR("uart_frame_pack failed: %d (node=%u, type=%u, len=%u)", frame_len, node_id, pkt_type, len);
        k_mutex_unlock(&tx_mutex);
        return -EINVAL;
    }

    int ret = uart_tx(s_uart_dev, dma_tx_buf, frame_len, SYS_FOREVER_US);
    if (ret < 0) {
        LOG_ERR("uart_tx failed: %d", ret);
        k_mutex_unlock(&tx_mutex);
        return ret;
    }

    ret = k_sem_take(&tx_done_sem, K_MSEC(100));
    if (ret != 0) {
        LOG_ERR("UART EasyDMA TX timeout, aborting transmission");
        uart_tx_abort(s_uart_dev);
    }

    k_mutex_unlock(&tx_mutex);
    return ret;
}

#endif
```

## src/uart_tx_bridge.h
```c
#pragma once

/* Standard C Libraries */
#include <stddef.h>
#include <stdint.h>
#include <stdbool.h>

#include "uart_frame_def.h"

typedef enum {
    CENTRAL_LINK_UNSYNCED = 0,
    CENTRAL_LINK_SYNCED   = 1,
} central_link_state_t;

typedef struct {
    central_link_state_t state;
    uint32_t             boot_nonce;
    uint64_t             active_epoch;
    uint32_t             snapshot_tx_id;
    uint32_t             hello_sent_count;
    uint32_t             sync_recv_count;
    uint32_t             stale_sync_drops;
} central_bridge_fsm_t;

void central_bridge_fsm_init(central_bridge_fsm_t *fsm, uint32_t boot_nonce);
int central_bridge_create_hello(central_bridge_fsm_t *fsm, uart_ctrl_hello_pkt_t *hello_out);
int central_bridge_handle_sync(central_bridge_fsm_t *fsm, const uart_ctrl_sync_pkt_t *sync);
int central_bridge_handle_snapshot_req(central_bridge_fsm_t *fsm, const uart_snapshot_req_pkt_t *req);
int central_bridge_create_snapshot_end(central_bridge_fsm_t *fsm, uart_snapshot_end_pkt_t *end_out);
void central_bridge_barrier_reset(central_bridge_fsm_t *fsm);
int central_bridge_dispatch_downlink(uint8_t node_id, const uint8_t *payload, uint8_t len);

#ifndef HOST_TEST
int uart_tx_bridge_init(void);
int uart_tx_bridge_send(const uint8_t *data, size_t len);
int uart_tx_bridge_send_frame(uint8_t node_id, uint8_t pkt_type, const void *payload, uint8_t len);
uint64_t uart_tx_bridge_get_active_epoch(void);
void uart_tx_bridge_poll_handshake(void);
#endif
```

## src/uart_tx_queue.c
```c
#include "uart_tx_queue.h"

#include <errno.h>
#include <string.h>

#ifdef HOST_TEST
#include "zephyr/kernel.h"
#else
#include <zephyr/kernel.h>
#include <zephyr/logging/log.h>
#include "uart_tx_bridge.h"

LOG_MODULE_REGISTER(uart_tx_queue, LOG_LEVEL_INF);
#endif

/* Message queue allocated statically in .bss (32 * 132B ≈ 4.2 KB) */
K_MSGQ_DEFINE(s_uart_tx_msgq, sizeof(uart_tx_item_t), UART_TX_QUEUE_DEPTH, 4);

/* Queue runtime statistics */
static uart_tx_queue_stats_t s_stats;

void uart_tx_queue_init(void) {
    k_msgq_purge(&s_uart_tx_msgq);
    memset(&s_stats, 0, sizeof(s_stats));
}

int uart_tx_queue_send(uint8_t node_id, uint8_t pkt_type, const void *payload, uint8_t len) {
    if (!payload || len == 0 || len > UART_MAX_PAYLOAD_LEN || node_id >= MAX_NODES_SUPPORTED) {
        return -EINVAL;
    }

    uart_tx_item_t item;
    item.node_id = node_id;
    item.pkt_type = pkt_type;
    item.len = len;
    memcpy(item.payload, payload, len);

    int ret = k_msgq_put(&s_uart_tx_msgq, &item, K_NO_WAIT);
    if (ret != 0) {
        s_stats.dropped_count++;
        return -ENOMEM;
    }

    s_stats.queued_count++;
    return 0;
}

int uart_tx_queue_get(uart_tx_item_t *item, int32_t timeout_ms) {
    if (!item) {
        return -EINVAL;
    }

    k_timeout_t timeout;
    if (timeout_ms < 0) {
        timeout = K_FOREVER;
    } else if (timeout_ms == 0) {
        timeout = K_NO_WAIT;
    } else {
        timeout = K_MSEC(timeout_ms);
    }

    return k_msgq_get(&s_uart_tx_msgq, item, timeout);
}

uint32_t uart_tx_queue_get_stats(uart_tx_queue_stats_t *stats) {
    if (stats) {
        *stats = s_stats;
    }
    return k_msgq_num_used_get(&s_uart_tx_msgq);
}

/* ══════════════════════════════════════════════════════════════
 *  Dedicated Consumer Worker Thread (Zephyr RTOS)
 *  Priority: 9 (Preemptible by BT RX Host thread priority 8)
 * ══════════════════════════════════════════════════════════════ */
#ifndef HOST_TEST
#define UART_TX_WORKER_STACK_SIZE 2048
#define UART_TX_WORKER_PRIORITY   K_PRIO_PREEMPT(9)

static void uart_tx_worker_entry(void *p1, void *p2, void *p3) {
    ARG_UNUSED(p1);
    ARG_UNUSED(p2);
    ARG_UNUSED(p3);

    uart_tx_item_t item;
    LOG_INF("UART TX Worker Thread started (Priority: %d, Stack: %u B)",
            UART_TX_WORKER_PRIORITY, UART_TX_WORKER_STACK_SIZE);

    while (1) {
        int ret = k_msgq_get(&s_uart_tx_msgq, &item, K_FOREVER);
        if (ret == 0) {
            uart_tx_bridge_send_frame(item.node_id, item.pkt_type, item.payload, item.len);
            s_stats.sent_count++;
        }
    }
}

K_THREAD_DEFINE(uart_tx_worker_tid, UART_TX_WORKER_STACK_SIZE,
                uart_tx_worker_entry, NULL, NULL, NULL,
                UART_TX_WORKER_PRIORITY, 0, 0);
#endif
```
